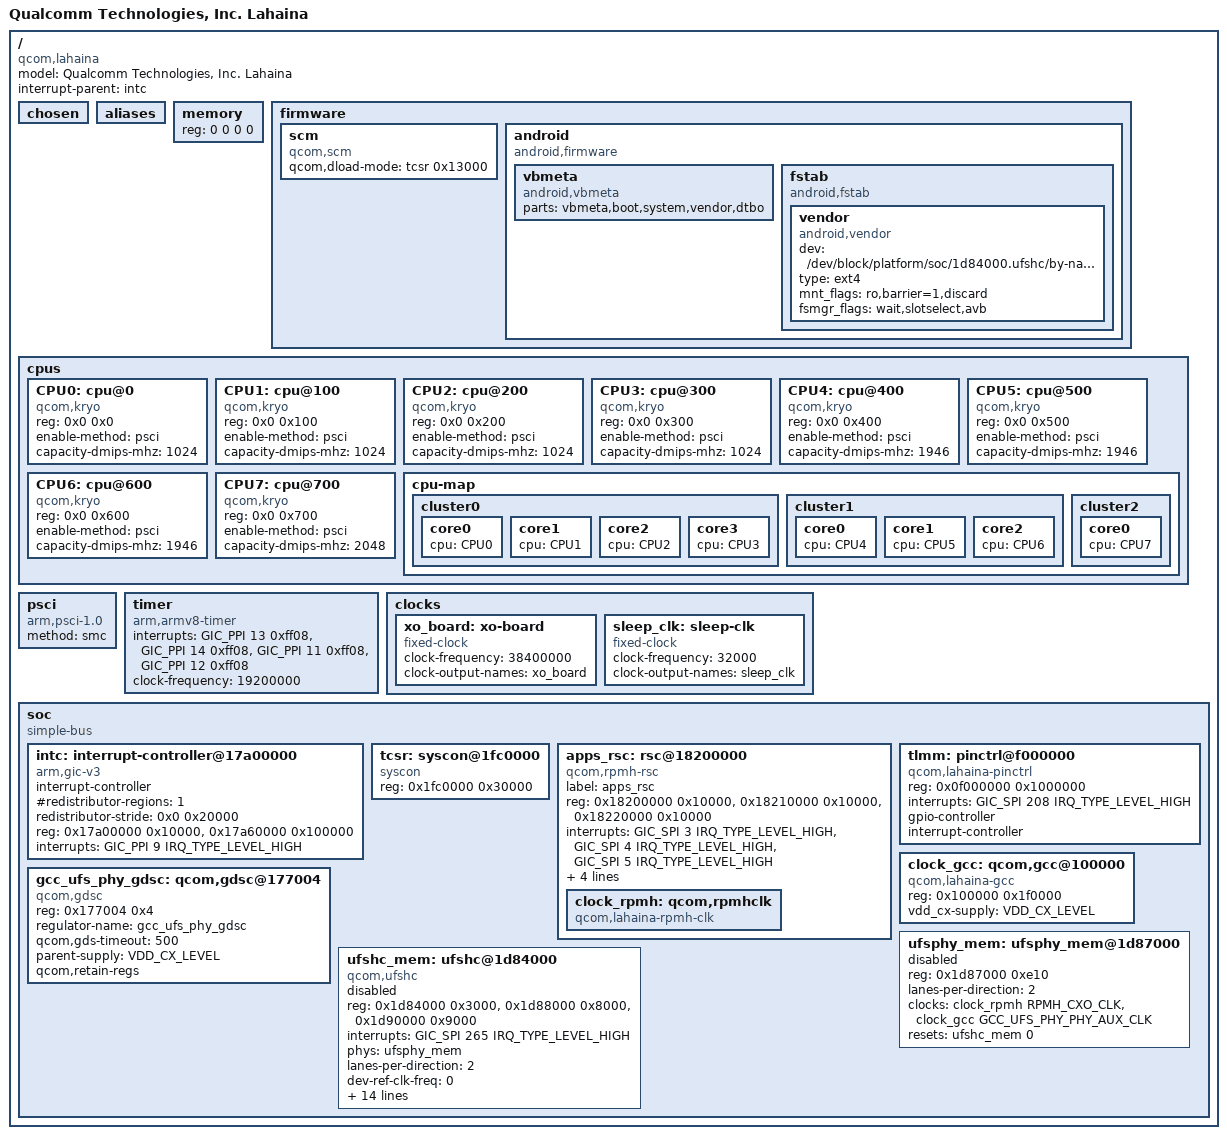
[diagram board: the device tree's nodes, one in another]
// SPDX-License-Identifier: GPL-2.0-only
/*
 * Lahaina (SM8350) SoC nodes for the 6.1 bring-up, ported from the 5.4
 * vendor lahaina.dtsi. Nodes are added here as their drivers get ported.
 */

#include <dt-bindings/clock/qcom,gcc-lahaina.h>
#include <dt-bindings/clock/qcom,rpmh.h>
#include <dt-bindings/gpio/gpio.h>
#include <dt-bindings/interrupt-controller/arm-gic.h>
#include <dt-bindings/regulator/qcom,rpmh-regulator-levels.h>
#include <dt-bindings/soc/qcom,rpmh-rsc.h>

/ {
	model = "Qualcomm Technologies, Inc. Lahaina";
	compatible = "qcom,lahaina";
	interrupt-parent = <&intc>;
	#address-cells = <2>;
	#size-cells = <2>;

	chosen: chosen { };

	aliases: aliases { };

	memory {
		device_type = "memory";
		/* filled in by ABL */
		reg = <0 0 0 0>;
	};

	firmware: firmware {
		scm {
			compatible = "qcom,scm";
			qcom,dload-mode = <&tcsr 0x13000>;
		};

		android {
			compatible = "android,firmware";

			vbmeta {
				compatible = "android,vbmeta";
				parts = "vbmeta,boot,system,vendor,dtbo";
			};

			fstab {
				compatible = "android,fstab";

				vendor {
					compatible = "android,vendor";
					dev = "/dev/block/platform/soc/1d84000.ufshc/by-name/vendor";
					type = "ext4";
					mnt_flags = "ro,barrier=1,discard";
					fsmgr_flags = "wait,slotselect,avb";
					status = "ok";
				};
			};
		};
	};

	cpus {
		#address-cells = <2>;
		#size-cells = <0>;

		CPU0: cpu@0 {
			device_type = "cpu";
			compatible = "qcom,kryo";
			reg = <0x0 0x0>;
			enable-method = "psci";
			capacity-dmips-mhz = <1024>;
		};

		CPU1: cpu@100 {
			device_type = "cpu";
			compatible = "qcom,kryo";
			reg = <0x0 0x100>;
			enable-method = "psci";
			capacity-dmips-mhz = <1024>;
		};

		CPU2: cpu@200 {
			device_type = "cpu";
			compatible = "qcom,kryo";
			reg = <0x0 0x200>;
			enable-method = "psci";
			capacity-dmips-mhz = <1024>;
		};

		CPU3: cpu@300 {
			device_type = "cpu";
			compatible = "qcom,kryo";
			reg = <0x0 0x300>;
			enable-method = "psci";
			capacity-dmips-mhz = <1024>;
		};

		CPU4: cpu@400 {
			device_type = "cpu";
			compatible = "qcom,kryo";
			reg = <0x0 0x400>;
			enable-method = "psci";
			capacity-dmips-mhz = <1946>;
		};

		CPU5: cpu@500 {
			device_type = "cpu";
			compatible = "qcom,kryo";
			reg = <0x0 0x500>;
			enable-method = "psci";
			capacity-dmips-mhz = <1946>;
		};

		CPU6: cpu@600 {
			device_type = "cpu";
			compatible = "qcom,kryo";
			reg = <0x0 0x600>;
			enable-method = "psci";
			capacity-dmips-mhz = <1946>;
		};

		CPU7: cpu@700 {
			device_type = "cpu";
			compatible = "qcom,kryo";
			reg = <0x0 0x700>;
			enable-method = "psci";
			capacity-dmips-mhz = <2048>;
		};

		cpu-map {
			cluster0 {
				core0 { cpu = <&CPU0>; };
				core1 { cpu = <&CPU1>; };
				core2 { cpu = <&CPU2>; };
				core3 { cpu = <&CPU3>; };
			};

			cluster1 {
				core0 { cpu = <&CPU4>; };
				core1 { cpu = <&CPU5>; };
				core2 { cpu = <&CPU6>; };
			};

			cluster2 {
				core0 { cpu = <&CPU7>; };
			};
		};
	};

	psci {
		compatible = "arm,psci-1.0";
		method = "smc";
	};

	timer {
		compatible = "arm,armv8-timer";
		interrupts = <GIC_PPI 13 0xff08>,
			     <GIC_PPI 14 0xff08>,
			     <GIC_PPI 11 0xff08>,
			     <GIC_PPI 12 0xff08>;
		clock-frequency = <19200000>;
	};

	clocks {
		xo_board: xo-board {
			compatible = "fixed-clock";
			#clock-cells = <0>;
			clock-frequency = <38400000>;
			clock-output-names = "xo_board";
		};

		sleep_clk: sleep-clk {
			compatible = "fixed-clock";
			#clock-cells = <0>;
			clock-frequency = <32000>;
			clock-output-names = "sleep_clk";
		};
	};

	soc: soc {
		compatible = "simple-bus";
		#address-cells = <1>;
		#size-cells = <1>;
		ranges = <0 0 0 0xffffffff>;

		intc: interrupt-controller@17a00000 {
			compatible = "arm,gic-v3";
			#interrupt-cells = <3>;
			interrupt-controller;
			#redistributor-regions = <1>;
			redistributor-stride = <0x0 0x20000>;
			reg = <0x17a00000 0x10000>,	/* GICD */
			      <0x17a60000 0x100000>;	/* GICR * 8 */
			interrupts = <GIC_PPI 9 IRQ_TYPE_LEVEL_HIGH>;
		};

		tcsr: syscon@1fc0000 {
			compatible = "syscon";
			reg = <0x1fc0000 0x30000>;
		};

		apps_rsc: rsc@18200000 {
			label = "apps_rsc";
			compatible = "qcom,rpmh-rsc";
			reg = <0x18200000 0x10000>,
			      <0x18210000 0x10000>,
			      <0x18220000 0x10000>;
			reg-names = "drv-0", "drv-1", "drv-2";
			interrupts = <GIC_SPI 3 IRQ_TYPE_LEVEL_HIGH>,
				     <GIC_SPI 4 IRQ_TYPE_LEVEL_HIGH>,
				     <GIC_SPI 5 IRQ_TYPE_LEVEL_HIGH>;
			qcom,tcs-offset = <0xd00>;
			qcom,drv-id = <2>;
			qcom,tcs-config = <ACTIVE_TCS  2>,
					  <SLEEP_TCS   3>,
					  <WAKE_TCS    3>,
					  <CONTROL_TCS 0>;

			clock_rpmh: qcom,rpmhclk {
				compatible = "qcom,lahaina-rpmh-clk";
				#clock-cells = <1>;
			};
		};

		tlmm: pinctrl@f000000 {
			compatible = "qcom,lahaina-pinctrl";
			reg = <0x0f000000 0x1000000>;
			interrupts = <GIC_SPI 208 IRQ_TYPE_LEVEL_HIGH>;
			gpio-controller;
			#gpio-cells = <2>;
			interrupt-controller;
			#interrupt-cells = <2>;
		};

		clock_gcc: qcom,gcc@100000 {
			compatible = "qcom,lahaina-gcc", "syscon";
			reg = <0x100000 0x1f0000>;
			reg-names = "cc_base";
			vdd_cx-supply = <&VDD_CX_LEVEL>;
			#clock-cells = <1>;
			#reset-cells = <1>;
		};

		gcc_ufs_phy_gdsc: qcom,gdsc@177004 {
			compatible = "qcom,gdsc";
			reg = <0x177004 0x4>;
			regulator-name = "gcc_ufs_phy_gdsc";
			qcom,gds-timeout = <500>;
			parent-supply = <&VDD_CX_LEVEL>;
			qcom,retain-regs;
		};

		ufsphy_mem: ufsphy_mem@1d87000 {
			reg = <0x1d87000 0xe10>;
			reg-names = "phy_mem";
			#phy-cells = <0>;

			lanes-per-direction = <2>;
			clock-names = "ref_clk_src",
				      "ref_aux_clk";
			clocks = <&clock_rpmh RPMH_CXO_CLK>,
				 <&clock_gcc GCC_UFS_PHY_PHY_AUX_CLK>;
			resets = <&ufshc_mem 0>;
			status = "disabled";
		};

		/*
		 * No interconnects or iommus yet: ABL's bus votes and SMMU
		 * setup are left as they are until those drivers are ported.
		 */
		ufshc_mem: ufshc@1d84000 {
			compatible = "qcom,ufshc";
			reg = <0x1d84000 0x3000>,
			      <0x1d88000 0x8000>,
			      <0x1d90000 0x9000>;
			reg-names = "ufs_mem", "ufs_ice", "ufs_ice_hwkm";
			interrupts = <GIC_SPI 265 IRQ_TYPE_LEVEL_HIGH>;
			phys = <&ufsphy_mem>;
			phy-names = "ufsphy";
			#reset-cells = <1>;

			lanes-per-direction = <2>;
			dev-ref-clk-freq = <0>; /* 19.2 MHz */
			clock-names =
				"core_clk",
				"bus_aggr_clk",
				"iface_clk",
				"core_clk_unipro",
				"core_clk_ice",
				"ref_clk",
				"tx_lane0_sync_clk",
				"rx_lane0_sync_clk",
				"rx_lane1_sync_clk";
			clocks =
				<&clock_gcc GCC_UFS_PHY_AXI_CLK>,
				<&clock_gcc GCC_AGGRE_UFS_PHY_AXI_CLK>,
				<&clock_gcc GCC_UFS_PHY_AHB_CLK>,
				<&clock_gcc GCC_UFS_PHY_UNIPRO_CORE_CLK>,
				<&clock_gcc GCC_UFS_PHY_ICE_CORE_CLK>,
				<&clock_rpmh RPMH_CXO_CLK>,
				<&clock_gcc GCC_UFS_PHY_TX_SYMBOL_0_CLK>,
				<&clock_gcc GCC_UFS_PHY_RX_SYMBOL_0_CLK>,
				<&clock_gcc GCC_UFS_PHY_RX_SYMBOL_1_CLK>;
			freq-table-hz =
				<75000000 300000000>,
				<0 0>,
				<0 0>,
				<75000000 300000000>,
				<75000000 300000000>,
				<0 0>,
				<0 0>,
				<0 0>,
				<0 0>;
			resets = <&clock_gcc GCC_UFS_PHY_BCR>;
			reset-names = "rst";
			dma-coherent;
			status = "disabled";
		};
	};
};

#include "lahaina-regulators.dtsi"
